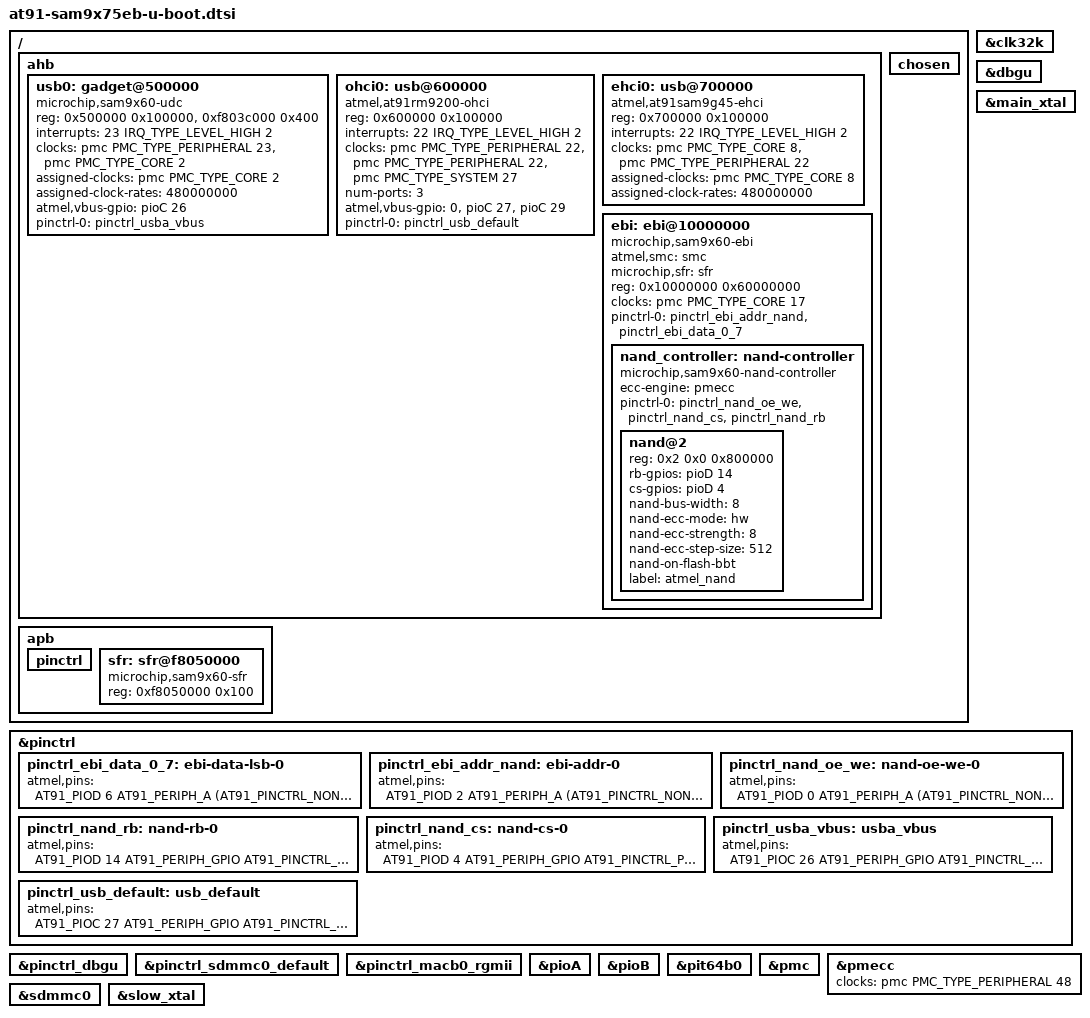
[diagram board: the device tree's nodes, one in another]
// SPDX-License-Identifier: (GPL-2.0+ OR MIT)
/*
 * at91-sam9x75eb-u-boot.dts - Device Tree file for SAM9X75-EB board.
 *
 * Copyright (C) 2022 Microchip Technology Inc. and its subsidiaries
 */

/ {
	ahb {
		bootph-all;

		usb0: gadget@500000 {
			compatible = "microchip,sam9x60-udc";
			reg = <0x500000 0x100000>,
			      <0xf803c000 0x400>;
			#address-cells = <1>;
			#size-cells = <0>;
			interrupts = <23 IRQ_TYPE_LEVEL_HIGH 2>;
			clocks = <&pmc PMC_TYPE_PERIPHERAL 23>, <&pmc PMC_TYPE_CORE 2>;
			clock-names = "pclk", "hclk";
			assigned-clocks = <&pmc PMC_TYPE_CORE 2>;
			assigned-clock-rates = <480000000>;
			atmel,vbus-gpio = <&pioC 26 GPIO_ACTIVE_HIGH>;
			pinctrl-names = "default";
			pinctrl-0 = <&pinctrl_usba_vbus>;
			status = "okay";
		};

		ohci0: usb@600000 {
			compatible = "atmel,at91rm9200-ohci", "usb-ohci";
			reg = <0x600000 0x100000>;
			interrupts = <22 IRQ_TYPE_LEVEL_HIGH 2>;
			clocks = <&pmc PMC_TYPE_PERIPHERAL 22>, <&pmc PMC_TYPE_PERIPHERAL 22>, <&pmc PMC_TYPE_SYSTEM 27>;
			clock-names = "ohci_clk", "hclk", "uhpck";
			num-ports = <3>;
			atmel,vbus-gpio = <0
					   &pioC 27 GPIO_ACTIVE_HIGH
					   &pioC 29 GPIO_ACTIVE_HIGH>;
			pinctrl-names = "default";
			pinctrl-0 = <&pinctrl_usb_default>;
			status = "okay";
		};

		ehci0: usb@700000 {
			compatible = "atmel,at91sam9g45-ehci", "usb-ehci";
			reg = <0x700000 0x100000>;
			interrupts = <22 IRQ_TYPE_LEVEL_HIGH 2>;
			clocks = <&pmc PMC_TYPE_CORE 8>, <&pmc PMC_TYPE_PERIPHERAL 22>;
			clock-names = "usb_clk", "ehci_clk";
			assigned-clocks = <&pmc PMC_TYPE_CORE 8>;
			assigned-clock-rates = <480000000>;
			status = "okay";
		};

		ebi: ebi@10000000 {
			compatible = "microchip,sam9x60-ebi";
			#address-cells = <2>;
			#size-cells = <1>;
			atmel,smc = <&smc>;
			microchip,sfr = <&sfr>;
			reg = <0x10000000 0x60000000>;
			ranges = <0x0 0x0 0x10000000 0x10000000
				  0x1 0x0 0x20000000 0x10000000
				  0x2 0x0 0x30000000 0x10000000>;
			clocks = <&pmc PMC_TYPE_CORE 17>;
			pinctrl-names = "default";
			pinctrl-0 = <&pinctrl_ebi_addr_nand &pinctrl_ebi_data_0_7>;
			status = "okay";

			nand_controller: nand-controller {
				compatible = "microchip,sam9x60-nand-controller";
				ecc-engine = <&pmecc>;
				#address-cells = <2>;
				#size-cells = <1>;
				ranges;
				pinctrl-names = "default";
				pinctrl-0 = <&pinctrl_nand_oe_we &pinctrl_nand_cs &pinctrl_nand_rb>;
				status = "okay";

				nand@2 {
					reg = <0x2 0x0 0x800000>;
					rb-gpios = <&pioD 14 GPIO_ACTIVE_HIGH>;
					cs-gpios = <&pioD 4 GPIO_ACTIVE_HIGH>;
					nand-bus-width = <8>;
					nand-ecc-mode = "hw";
					nand-ecc-strength = <8>;
					nand-ecc-step-size = <512>;
					nand-on-flash-bbt;
					label = "atmel_nand";
				};
			};
		};
	};

    apb {
        bootph-all;

        pinctrl {
            bootph-all;
        };

        sfr: sfr@f8050000 {
            compatible = "microchip,sam9x60-sfr", "syscon";
            reg = <0xf8050000 0x100>;
        };
    };

	chosen {
		bootph-all;
	};
};

&clk32k {
	bootph-all;
};

&dbgu {
	bootph-all;
};

&main_xtal {
	bootph-all;
};

&pinctrl {

	pinctrl_ebi_data_0_7: ebi-data-lsb-0 {
		atmel,pins =
			<AT91_PIOD 6 AT91_PERIPH_A (AT91_PINCTRL_NONE | AT91_PINCTRL_SLEWRATE_DIS)
			 AT91_PIOD 7 AT91_PERIPH_A (AT91_PINCTRL_NONE | AT91_PINCTRL_SLEWRATE_DIS)
			 AT91_PIOD 8 AT91_PERIPH_A (AT91_PINCTRL_NONE | AT91_PINCTRL_SLEWRATE_DIS)
			 AT91_PIOD 9 AT91_PERIPH_A (AT91_PINCTRL_NONE | AT91_PINCTRL_SLEWRATE_DIS)
			 AT91_PIOD 10 AT91_PERIPH_A (AT91_PINCTRL_NONE | AT91_PINCTRL_SLEWRATE_DIS)
			 AT91_PIOD 11 AT91_PERIPH_A (AT91_PINCTRL_NONE | AT91_PINCTRL_SLEWRATE_DIS)
			 AT91_PIOD 12 AT91_PERIPH_A (AT91_PINCTRL_NONE | AT91_PINCTRL_SLEWRATE_DIS)
			 AT91_PIOD 13 AT91_PERIPH_A (AT91_PINCTRL_NONE | AT91_PINCTRL_SLEWRATE_DIS)>;
	};

	pinctrl_ebi_addr_nand: ebi-addr-0 {
		atmel,pins =
			<AT91_PIOD 2 AT91_PERIPH_A (AT91_PINCTRL_NONE | AT91_PINCTRL_SLEWRATE_DIS)
			 AT91_PIOD 3 AT91_PERIPH_A (AT91_PINCTRL_NONE | AT91_PINCTRL_SLEWRATE_DIS)>;
	};

	pinctrl_nand_oe_we: nand-oe-we-0 {
		atmel,pins =
			<AT91_PIOD 0 AT91_PERIPH_A (AT91_PINCTRL_NONE | AT91_PINCTRL_SLEWRATE_DIS)
			 AT91_PIOD 1 AT91_PERIPH_A (AT91_PINCTRL_NONE | AT91_PINCTRL_SLEWRATE_DIS)>;
	};

	pinctrl_nand_rb: nand-rb-0 {
		atmel,pins =
			<AT91_PIOD 14 AT91_PERIPH_GPIO AT91_PINCTRL_PULL_UP>;
	};

	pinctrl_nand_cs: nand-cs-0 {
		atmel,pins =
			<AT91_PIOD 4 AT91_PERIPH_GPIO AT91_PINCTRL_PULL_UP>;
	};

	pinctrl_usba_vbus: usba_vbus {
		atmel,pins = <AT91_PIOC 26 AT91_PERIPH_GPIO AT91_PINCTRL_NONE>;
	};

	pinctrl_usb_default: usb_default {
		atmel,pins = <AT91_PIOC 27 AT91_PERIPH_GPIO AT91_PINCTRL_NONE
		AT91_PIOC 29 AT91_PERIPH_GPIO AT91_PINCTRL_NONE>;
	};
};

&pinctrl_dbgu {
	bootph-all;
};

&pinctrl_sdmmc0_default {
	bootph-all;
};

&pinctrl_macb0_rgmii {
	bootph-all;
};

&pioA {
	bootph-all;
};

&pioB {
	bootph-all;
};

&pit64b0 {
	bootph-all;
};

&pmc {
	bootph-all;
};

&pmecc {
	clocks = <&pmc PMC_TYPE_PERIPHERAL 48>;
};

&sdmmc0 {
	bootph-all;
};

&slow_xtal {
	bootph-all;
};
